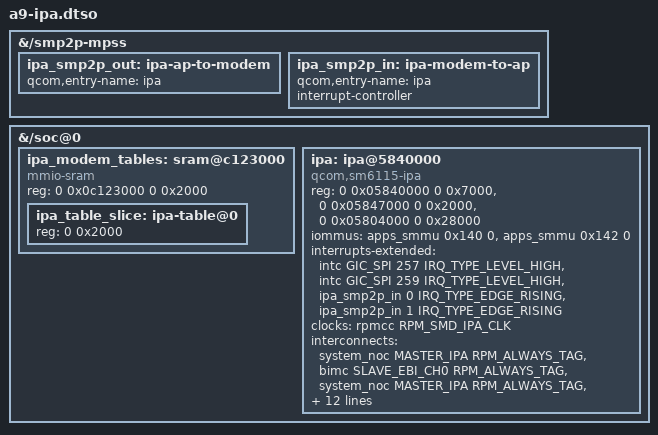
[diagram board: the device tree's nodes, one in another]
// SPDX-License-Identifier: (GPL-2.0-only OR BSD-2-Clause)
/dts-v1/;
/plugin/;

#include <dt-bindings/clock/qcom,rpmcc.h>
#include <dt-bindings/interconnect/qcom,sm6115.h>
#include <dt-bindings/interconnect/qcom,rpm-icc.h>
#include <dt-bindings/interrupt-controller/arm-gic.h>

/* Stock Hisense A9 base DTB: IPA4.2, PAS15, SID0x140/0x142, IRQ257/259.
 * Downstream ipahal adds 0x40000 to wrapper0x5800000; SRAM is +0x7000.
 * Keep every existing R4 reservation and firmware/power consumer unchanged.
 */
&{/smp2p-mpss} {
    ipa_smp2p_out: ipa-ap-to-modem {
        qcom,entry-name = "ipa";
        #qcom,smem-state-cells = <1>;
    };
    ipa_smp2p_in: ipa-modem-to-ap {
        qcom,entry-name = "ipa";
        interrupt-controller;
        #interrupt-cells = <2>;
    };
};

&{/soc@0} {
    #address-cells = <2>;
    #size-cells = <2>;
    /* Dedicated IPA modem table area from stock's additional-mapping. */
    ipa_modem_tables: sram@c123000 {
        compatible = "mmio-sram";
        reg = <0 0x0c123000 0 0x2000>;
        #address-cells = <1>;
        #size-cells = <1>;
        ranges = <0 0 0x0c123000 0x2000>;
        ipa_table_slice: ipa-table@0 {
            reg = <0 0x2000>;
        };
    };
    ipa: ipa@5840000 {
        compatible = "qcom,sm6115-ipa", "qcom,sc7180-ipa";
        reg = <0 0x05840000 0 0x7000>,
              <0 0x05847000 0 0x2000>,
              <0 0x05804000 0 0x28000>;
        reg-names = "ipa-reg", "ipa-shared", "gsi";
        iommus = <&apps_smmu 0x140 0>, <&apps_smmu 0x142 0>;
        interrupts-extended = <&intc GIC_SPI 257 IRQ_TYPE_LEVEL_HIGH>,
                              <&intc GIC_SPI 259 IRQ_TYPE_LEVEL_HIGH>,
                              <&ipa_smp2p_in 0 IRQ_TYPE_EDGE_RISING>,
                              <&ipa_smp2p_in 1 IRQ_TYPE_EDGE_RISING>;
        interrupt-names = "ipa", "gsi", "ipa-clock-query", "ipa-setup-ready";
        clocks = <&rpmcc RPM_SMD_IPA_CLK>;
        clock-names = "core";
        interconnects = <&system_noc MASTER_IPA RPM_ALWAYS_TAG
                         &bimc SLAVE_EBI_CH0 RPM_ALWAYS_TAG>,
                        <&system_noc MASTER_IPA RPM_ALWAYS_TAG
                         &system_noc SLAVE_OCIMEM RPM_ALWAYS_TAG>,
                        <&bimc MASTER_AMPSS_M0 RPM_ALWAYS_TAG
                         &config_noc SLAVE_IPA_CFG RPM_ALWAYS_TAG>;
        interconnect-names = "memory", "imem", "config";
        qcom,smem-states = <&ipa_smp2p_out 0>, <&ipa_smp2p_out 1>;
        qcom,smem-state-names = "ipa-clock-enabled-valid", "ipa-clock-enabled";
        qcom,gsi-loader = "self";
        memory-region = <&a9_stock_ipa_fw_mem>;
        firmware-name = "qcom/sm6115/hisense/hlte556n/ipa_fws.mdt";
        sram = <&ipa_table_slice>;
        status = "okay";
    };
};
